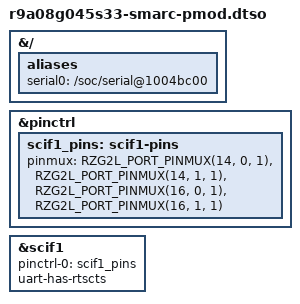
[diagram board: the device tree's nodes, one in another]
// SPDX-License-Identifier: GPL-2.0
/*
 * Device Tree Source for the RZ/G3S SMARC Carrier II EVK PMOD parts
 *
 * Copyright (C) 2024 Renesas Electronics Corp.
 *
 *
 * [Connection]
 *
 * SMARC Carrier II EVK
 * +--------------------------------------------+
 * |PMOD1_3A (PMOD1 PIN HEADER)			|
 * |	SCIF1_CTS# (pin1)  (pin7)  PMOD1_GPIO10	|
 * |	SCIF1_TXD  (pin2)  (pin8)  PMOD1_GPIO11	|
 * |	SCIF1_RXD  (pin3)  (pin9)  PMOD1_GPIO12	|
 * |	SCIF1_RTS# (pin4)  (pin10) PMOD1_GPIO13	|
 * |	GND	   (pin5)  (pin11) GND		|
 * |	PWR_PMOD1  (pin6)  (pin12) GND		|
 * +--------------------------------------------+
 *
 */

/dts-v1/;
/plugin/;

#include <dt-bindings/pinctrl/rzg2l-pinctrl.h>

&{/} {
	aliases {
		serial0 = "/soc/serial@1004bc00";
	};
};

&pinctrl {
	scif1_pins: scif1-pins {
		pinmux = <RZG2L_PORT_PINMUX(14, 0, 1)>, /* TXD */
			 <RZG2L_PORT_PINMUX(14, 1, 1)>, /* RXD */
			 <RZG2L_PORT_PINMUX(16, 0, 1)>, /* CTS */
			 <RZG2L_PORT_PINMUX(16, 1, 1)>; /* RTS */
	};
};

&scif1 {
	pinctrl-names = "default";
	pinctrl-0 = <&scif1_pins>;
	uart-has-rtscts;
	status = "okay";
};
